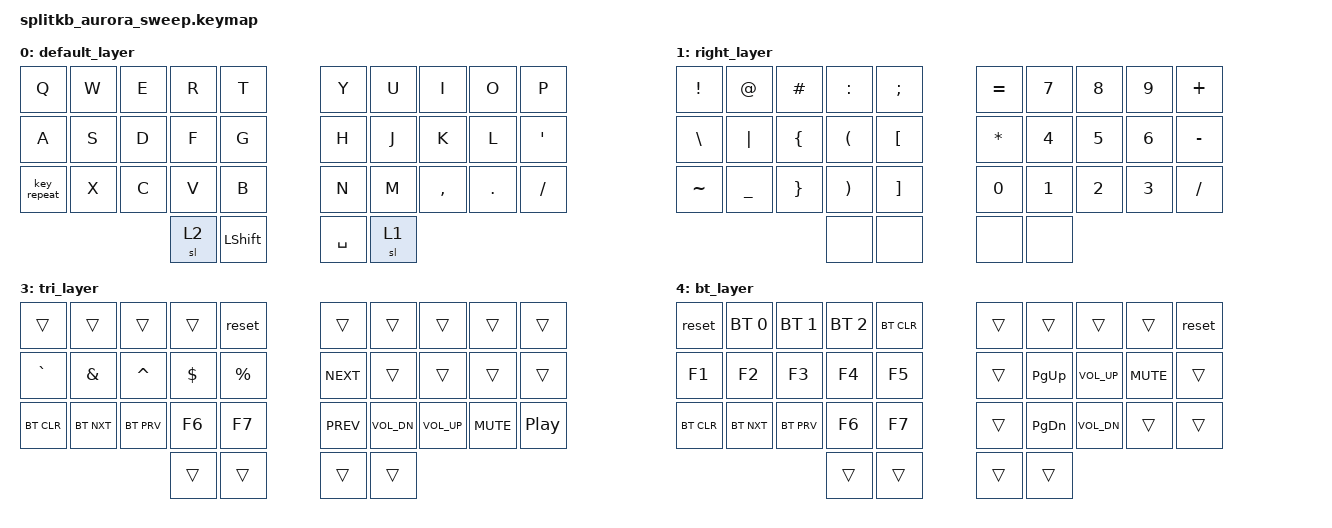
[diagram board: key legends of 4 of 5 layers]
/*
 * Copyright (c) 2022 The ZMK Contributors
 *
 * SPDX-License-Identifier: MIT
 */

#include <behaviors.dtsi>
#include <dt-bindings/zmk/keys.h>
#include <dt-bindings/zmk/bt.h>


&mt {
  //  flavor = "tap-preferred";
   // tapping_term_ms = <200>;
};

&key_repeat {
    usage-pages = <HID_USAGE_KEY HID_USAGE_CONSUMER>;
};

/ { 
    combos {
        compatible = "zmk,combos";
        combo_esc {
            timeout-ms = <50>;
            key-positions = <0 1>;
            // Q+W
            bindings = <&kp ESC>;
        };

        combo_bspcword {
            timeout-ms = <50>;
            key-positions = <13 16>;
            // F+J
            bindings = <&kp LA(BSPC)>;
        };

        combo_delword {
            timeout-ms = <50>;
            key-positions = <12 17>;
            // D+K
            bindings = <&kp LA(DEL)>;
        };
        
         combo_lctrl {
            timeout-ms = <50>;
            key-positions = <10 11>;
            // A+S
            bindings = <&kp LCTRL>;
        };

        combo_z {
            timeout-ms = <60>;
            key-positions = <20 29>;
            //Z+?
            bindings = <&kp Z>;
            layers = <0>;
          };

         combo_x {
            timeout-ms = <60>;
            key-positions = <22 23>;
            //C+V 
            bindings = <&kp X>;
            layers = <0>;
        };

         combo_UNDER {
            timeout-ms = <60>;
            key-positions = <22 23>;
            //UNDERSCORE (C+V)
            bindings = <&kp UNDER>;
            layers = <1>;
        };

         combo_rctrl {
            timeout-ms = <50>;
            key-positions = <18 19>;
            // L+'
            bindings = <&kp RCTRL>;
        };

          combo_laltctr {
            timeout-ms = <50>;
            key-positions = <11 12>;
            // S+D
            bindings = <&kp LC(LALT)>;
        };
        
          combo_raltctr {
            timeout-ms = <50>;
            key-positions = <17 18>;
            // K+L
            bindings = <&kp RC(RALT)>;
        };

          combo_ctrl_opt {
            timeout-ms = <50>;
            key-positions = <11 12>;
            // S+D
            bindings = <&sk LC(LALT)>;
            layer = <1>;
        };

          combo_ctrl_cmd {
            timeout-ms = <50>;
            key-positions = <11 13>;
            // S+F
            bindings = <&sk LC(LALT)>;
            layer = <1>;
        };
        
    };

    conditional_layers {
        compatible = "zmk,conditional-layers";
        tri_layer {
            if-layers = <1 2>;
            then-layer = <3>;
        };
    };

        keymap {
                compatible = "zmk,keymap";
                
       		default_layer {
		bindings = <
		&kp Q &kp W &kp E &kp R &kp T 						            &kp Y &kp U  &kp I    &kp O   &kp P 
		&kp A &kp S &kp D &kp F &kp G 			        	        &kp H &kp J &kp K &kp L &kp QUOT
		&key_repeat &kp X &kp C &kp V &kp B		                &kp N &kp M  &kp CMMA &kp DOT &kp FSLH
                    &sl 2   &kp LSHFT                     &kp SPACE  &sl 1
		>;
		};

		right_layer {
		bindings = <
    &kp EXCL   &kp AT     &kp HASH   &kp COLON  &kp SEMI       &kp EQUAL  &kp N7    &kp N8      &kp N9     &kp PLUS
    &kp BSLH   &kp PIPE   &kp LBRC   &kp LPAR   &kp LBKT       &kp STAR   &kp N4     &kp N5     &kp N6     &kp MINUS
    &kp TILDE &kp UNDER  &kp RBRC   &kp RPAR   &kp RBKT       &kp N0    &kp N1     &kp N2      &kp N3     &kp FSLH
                                    &none       &none          &none      &none
		>;
		};	
          
    left_layer {
		bindings = <
    &kp ESC   &kp LMETA  &kp LA(LG(C))   &caps_word   &sk LG(LS(LCTRL))        &kp LG(TAB) &kp LG(LS(LBKT)) &kp LG(LS(RBKT))  &trans  &kp LC(U) 
    &sk LSHFT &sk LCTRL   &sk LALT   &sk LCMD    &sk LG(LCTRL)         &kp LEFT   &kp DOWN    &kp UP    &kp RIGHT  &kp LC(D) 
    &kp LG(Z)  &kp LG(X)  &kp LG(C) &kp LG(V)    &none         &kp DEL  &kp BSPC    &kp TAB   &kp LC(BSLH)  &kp RET
                                    &none       &lt 0       &trans   &sk LG(LS(LC(LALT)))
		>;
		};
		
		tri_layer {
		bindings = <
    &trans     &trans     &trans     &trans    &reset     &trans     &trans     &trans     &trans    &trans
    &kp GRAVE  &kp AMPS   &kp CARET   &kp DLLR     &kp PRCNT      &kp C_NEXT     &trans     &trans    &trans &trans
		&bt BT_CLR  &bt BT_NXT &bt BT_PRV &kp F6 &kp F7   				&kp C_PREV &kp C_VOL_DN     &kp C_VOL_UP  &kp K_MUTE &kp C_PLAY_PAUSE  
		                           			 &trans &trans  					&trans &trans 
		>;
		};	

		bt_layer {
		bindings = <
    &reset &bt BT_SEL 0 &bt BT_SEL 1 &bt BT_SEL 2 &bt BT_CLR      &trans     &trans     &trans     &trans    &reset
		&kp F1 &kp F2 &kp F3 &kp F4 &kp F5  						&trans &kp PG_UP  &kp K_VOL_UP &kp K_MUTE &trans 
		&bt BT_CLR  &bt BT_NXT &bt BT_PRV &kp F6 &kp F7   				&trans &kp PG_DN  &kp K_VOL_DN  &trans &trans   
					                              &trans &trans  					&trans &trans 
		>;
		};	

	};
};
